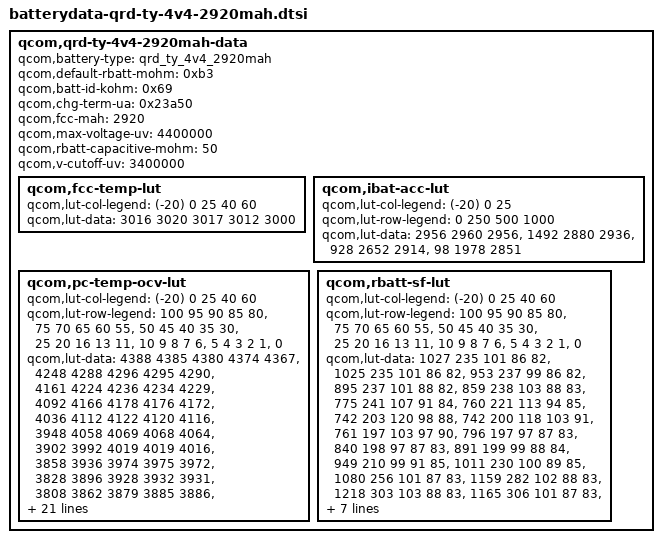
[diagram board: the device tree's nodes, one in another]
/* Copyright (c) 2015, The Linux Foundation. All rights reserved.
 *
 * This program is free software; you can redistribute it and/or modify
 * it under the terms of the GNU General Public License version 2 and
 * only version 2 as published by the Free Software Foundation.
 *
 * This program is distributed in the hope that it will be useful,
 * but WITHOUT ANY WARRANTY; without even the implied warranty of
 * MERCHANTABILITY or FITNESS FOR A PARTICULAR PURPOSE.  See the
 * GNU General Public License for more details.
 */

qcom,qrd-ty-4v4-2920mah-data {
	qcom,battery-type = "qrd_ty_4v4_2920mah";
	qcom,default-rbatt-mohm = < 0xb3 >;
	qcom,batt-id-kohm = < 0x69 >;
	qcom,chg-term-ua = < 0x23a50 >;
	qcom,fcc-mah = <2920>;
	qcom,max-voltage-uv = <4400000>;
	qcom,rbatt-capacitive-mohm = <50>;
	qcom,v-cutoff-uv = <3400000>;

	qcom,fcc-temp-lut {
		qcom,lut-col-legend = <(-20) 0 25 40 60>;
		qcom,lut-data = <3016 3020 3017 3012 3000>;
	};

	qcom,ibat-acc-lut {
		qcom,lut-col-legend = <(-20) 0 25>;
		qcom,lut-row-legend = <0 250 500 1000>;
		qcom,lut-data = <2956 2960 2956>,
			<1492 2880 2936>,
			<928 2652 2914>,
			<98 1978 2851>;
	};

	qcom,pc-temp-ocv-lut {
		qcom,lut-col-legend = <(-20) 0 25 40 60>;
		qcom,lut-row-legend = <100 95 90 85 80>,
					<75 70 65 60 55>,
					<50 45 40 35 30>,
					<25 20 16 13 11>,
					<10 9 8 7 6>,
					<5 4 3 2 1>,
					<0>;
		qcom,lut-data = <4388 4385 4380 4374 4367>,
				<4248 4288 4296 4295 4290>,
				<4161 4224 4236 4234 4229>,
				<4092 4166 4178 4176 4172>,
				<4036 4112 4122 4120 4116>,
				<3948 4058 4069 4068 4064>,
				<3902 3992 4019 4019 4016>,
				<3858 3936 3974 3975 3972>,
				<3828 3896 3928 3932 3931>,
				<3808 3862 3879 3885 3886>,
				<3793 3832 3844 3846 3845>,
				<3779 3808 3820 3820 3820>,
				<3765 3789 3800 3801 3800>,
				<3749 3776 3784 3784 3783>,
				<3734 3765 3771 3770 3764>,
				<3718 3750 3758 3752 3740>,
				<3702 3728 3740 3733 3719>,
				<3684 3708 3718 3710 3697>,
				<3669 3696 3693 3686 3675>,
				<3652 3690 3686 3680 3669>,
				<3643 3686 3684 3678 3668>,
				<3631 3682 3683 3678 3667>,
				<3618 3678 3682 3676 3665>,
				<3600 3673 3678 3674 3662>,
				<3580 3663 3672 3668 3654>,
				<3554 3643 3653 3644 3626>,
				<3516 3604 3608 3598 3580>,
				<3462 3540 3547 3534 3516>,
				<3377 3451 3455 3448 3430>,
				<3240 3308 3318 3318 3297>,
				<3000 3000 3000 3000 3000>;
	};

	qcom,rbatt-sf-lut {
		qcom,lut-col-legend = <(-20) 0 25 40 60>;
		qcom,lut-row-legend = <100 95 90 85 80>,
					<75 70 65 60 55>,
					<50 45 40 35 30>,
					<25 20 16 13 11>,
					<10 9 8 7 6>,
					<5 4 3 2 1>,
					<0>;
		qcom,lut-data = <1027 235 101 86 82>,
				<1025 235 101 86 82>,
				<953 237 99 86 82>,
				<895 237 101 88 82>,
				<859 238 103 88 83>,
				<775 241 107 91 84>,
				<760 221 113 94 85>,
				<742 203 120 98 88>,
				<742 200 118 103 91>,
				<761 197 103 97 90>,
				<796 197 97 87 83>,
				<840 198 97 87 83>,
				<891 199 99 88 84>,
				<949 210 99 91 85>,
				<1011 230 100 89 85>,
				<1080 256 101 87 83>,
				<1159 282 102 88 83>,
				<1218 303 103 88 83>,
				<1165 306 101 87 83>,
				<1223 323 101 87 83>,
				<1261 337 102 88 83>,
				<1306 354 105 89 84>,
				<1358 377 108 91 86>,
				<1460 402 111 92 88>,
				<1635 429 116 94 88>,
				<1906 459 117 93 86>,
				<2322 489 117 93 86>,
				<2979 545 124 96 88>,
				<4326 636 139 104 96>,
				<8651 1085 251 140 114>,
				<17303 2170 502 280 228>;
	};
};
